# ATSAM4N16C register map
Vendor: Atmel; Series: SAM4N; File version: 0
CPU: CM4 r0p1, selectable endian, MPU, no FPU, 4 interrupt priority bits
Registers are 32-bit, read-write, reset 0x0 unless marked. A register's access mark holds for its fields unless they carry their own. Offsets are from the block's base; [hi:lo] are bit positions; {n}, {i} and the like mark numbered series; 'fields as' and 'values as' point back to an identical list.

## ADC — Analog-to-Digital Converter
Base 0x40038000; register names take the prefix ADC_
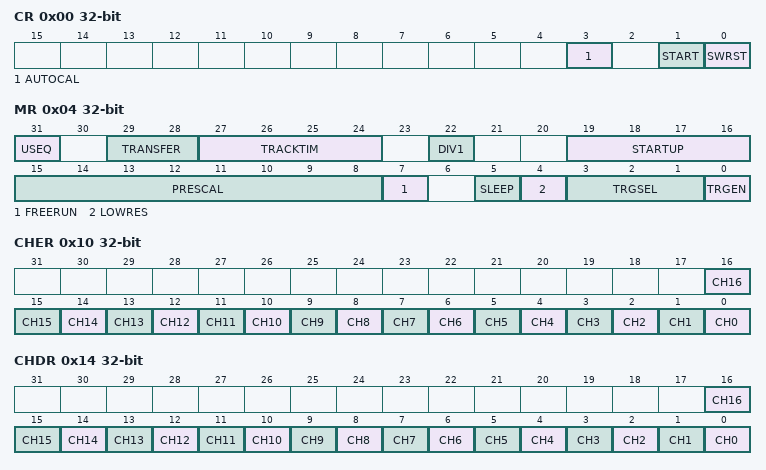
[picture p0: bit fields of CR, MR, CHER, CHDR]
0x00 CR wo reset not defined — Control Register
  [3] AUTOCAL — Automatic Calibration of ADC
  [1] START — Start Conversion
  [0] SWRST — Software Reset
0x04 MR — Mode Register
  [31] USEQ — Use Sequence Enable
    0=NUM_ORDER (Normal Mode: The controller converts channels in a simple numeric order depending only on the channel index.); 1=REG_ORDER (User Sequence Mode: The sequence respects what is defined in ADC_SEQR1 and ADC_SEQR2 registers and can be used to convert several times the same channel.)
  [29:28] TRANSFER — Transfer Period
  [27:24] TRACKTIM — Tracking Time
  [22] DIV1
  [19:16] STARTUP — Start Up Time
    0=SUT0 (0 periods of ADCClock); 1=SUT8 (8 periods of ADCClock); 2=SUT16 (16 periods of ADCClock); 3=SUT24 (24 periods of ADCClock); 4=SUT64 (64 periods of ADCClock); 5=SUT80 (80 periods of ADCClock); 6=SUT96 (96 periods of ADCClock); 7=SUT112 (112 periods of ADCClock); 8=SUT512 (512 periods of ADCClock); 9=SUT576 (576 periods of ADCClock); 10=SUT640 (640 periods of ADCClock); 11=SUT704 (704 periods of ADCClock); 12=SUT768 (768 periods of ADCClock); 13=SUT832 (832 periods of ADCClock); 14=SUT896 (896 periods of ADCClock); 15=SUT960 (960 periods of ADCClock)
  [15:8] PRESCAL — Prescaler Rate Selection
  [7] FREERUN — Free Run Mode
    0=OFF (Normal Mode); 1=ON (Free Run Mode: Never wait for any trigger.)
  [5] SLEEP — Sleep Mode
    0=NORMAL (Normal Mode: The ADC Core and reference voltage circuitry are kept ON between conversions); 1=SLEEP (Sleep Mode: The ADC Core and reference voltage circuitry are OFF between conversions)
  [4] LOWRES — Resolution
    0=BITS_10 (10-bit resolution. For higher resolution by interpolation, please refer to "ADC Extended Mode Register" on page 81); 1=BITS_8 (8-bit resolution)
  [3:1] TRGSEL — Trigger Selection
    0=ADC_TRIG0 (External trigger); 1=ADC_TRIG1 (TIO Output of the Timer Counter Channel 0); 2=ADC_TRIG2 (TIO Output of the Timer Counter Channel 1); 3=ADC_TRIG3 (TIO Output of the Timer Counter Channel 2)
  [0] TRGEN — Trigger Enable
    0=DIS (Hardware triggers are disabled. Starting a conversion is only possible by software.); 1=EN (Hardware trigger selected by TRGSEL field is enabled.)
{0x8+4i} SEQR[{i}] (i=0..1) reset not defined — Channel Sequence Register
0x10 CHER wo reset not defined — Channel Enable Register
  [n] CH{n} (n=0..16) — Channel {n} Enable
0x14 CHDR wo reset not defined — Channel Disable Register
  [n] CH{n} (n=0..16) — Channel {n} Disable
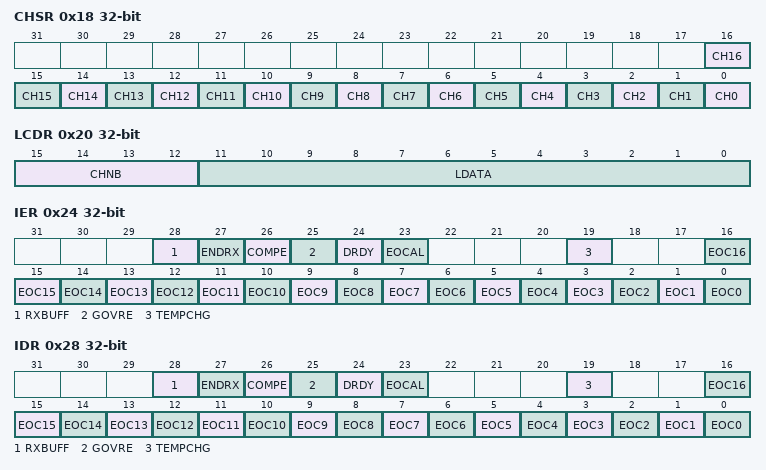
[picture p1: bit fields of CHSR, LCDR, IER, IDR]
0x18 CHSR ro — Channel Status Register
  [n] CH{n} (n=0..16) — Channel {n} Status
0x20 LCDR ro — Last Converted Data Register
  [15:12] CHNB — Channel Number
  [11:0] LDATA — Last Data Converted
0x24 IER wo reset not defined — Interrupt Enable Register
  [28] RXBUFF — Receive Buffer Full Interrupt Enable
  [27] ENDRX — End of Receive Buffer Interrupt Enable
  [26] COMPE — Comparison Event Interrupt Enable
  [25] GOVRE — General Overrun Error Interrupt Enable
  [24] DRDY — Data Ready Interrupt Enable
  [23] EOCAL — End of Calibration Sequence
  [19] TEMPCHG — Temperature Change Interrupt Enable
  [n] EOC{n} (n=0..16) — End of Conversion Interrupt Enable {n}
0x28 IDR wo reset not defined — Interrupt Disable Register
  [28] RXBUFF — Receive Buffer Full Interrupt Disable
  [27] ENDRX — End of Receive Buffer Interrupt Disable
  [26] COMPE — Comparison Event Interrupt Disable
  [25] GOVRE — General Overrun Error Interrupt Disable
  [24] DRDY — Data Ready Interrupt Disable
  [23] EOCAL — End of Calibration Sequence
  [19] TEMPCHG — Temperature Change Interrupt Disable
  [n] EOC{n} (n=0..16) — End of Conversion Interrupt Disable {n}
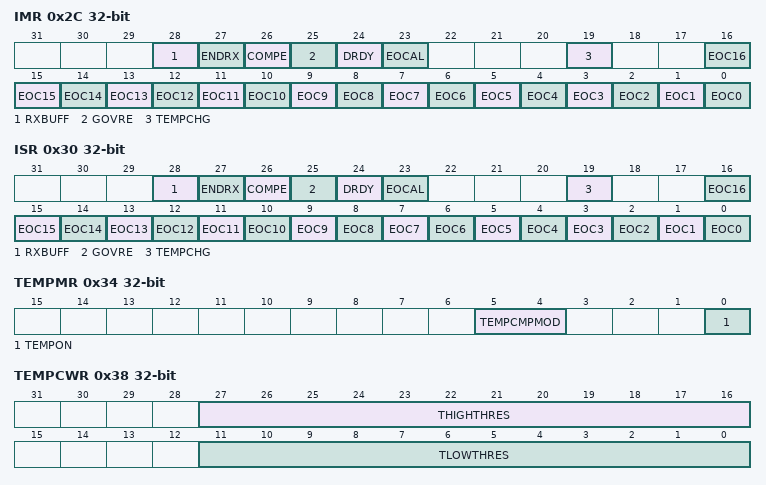
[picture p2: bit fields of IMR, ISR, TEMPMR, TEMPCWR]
0x2C IMR ro — Interrupt Mask Register
  [28] RXBUFF — Receive Buffer Full Interrupt Mask
  [27] ENDRX — End of Receive Buffer Interrupt Mask
  [26] COMPE — Comparison Event Interrupt Mask
  [25] GOVRE — General Overrun Error Interrupt Mask
  [24] DRDY — Data Ready Interrupt Mask
  [23] EOCAL — End of Calibration Sequence
  [19] TEMPCHG — Temperature Change Interrupt Mask
  [n] EOC{n} (n=0..16) — End of Conversion Interrupt Mask {n}
0x30 ISR ro — Interrupt Status Register
  [28] RXBUFF — RX Buffer Full
  [27] ENDRX — End of RX Buffer
  [26] COMPE — Comparison Error
  [25] GOVRE — General Overrun Error
  [24] DRDY — Data Ready
  [23] EOCAL — End of Calibration Sequence
  [19] TEMPCHG — Temperature Change
  [n] EOC{n} (n=0..16) — End of Conversion {n}
0x34 TEMPMR — Temperature Sensor Mode Register
  [5:4] TEMPCMPMOD — Temperature Comparison Mode
    0=LOW (Generates an event when the converted data is lower than the low threshold of the window.); 1=HIGH (Generates an event when the converted data is higher than the high threshold of the window.); 2=IN (Generates an event when the converted data is in the comparison window.); 3=OUT (Generates an event when the converted data is out of the comparison window.)
  [0] TEMPON — Temperature Sensor ON
0x38 TEMPCWR — Temperature Compare Window Register
  [27:16] THIGHTHRES — Temperature High Threshold
  [11:0] TLOWTHRES — Temperature Low Threshold
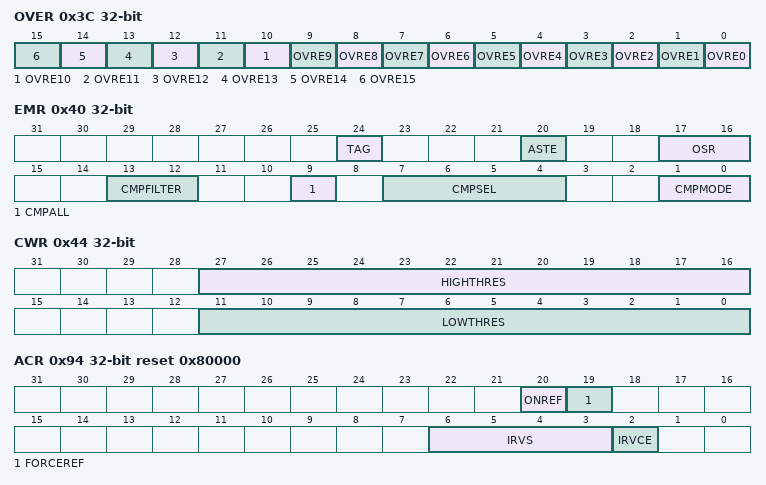
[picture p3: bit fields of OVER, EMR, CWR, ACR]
0x3C OVER ro — Overrun Status Register
  [n] OVRE{n} (n=0..15) — Overrun Error {n}
0x40 EMR — Extended Mode Register
  [24] TAG — TAG of the ADC_LDCR register
  [20] ASTE — Averaging on Single Trigger Event
    0=MULTI_TRIG_AVERAGE (The average requests several trigger events.); 1=SINGLE_TRIG_AVERAGE (The average requests only one trigger event.)
  [17:16] OSR — Over Sampling Rate
    0=NO_AVERAGE (no averaging. ADC sample rate is maximum.); 1=1-bit enhanced resolution by interpolation. ADC sample rate divided by 4.; 2=2-bit enhanced resolution by interpolation. ADC sample rate divided by 16.
  [13:12] CMPFILTER — Compare Event Filtering
  [9] CMPALL — Compare All Channels
  [7:4] CMPSEL — Comparison Selected Channel
  [1:0] CMPMODE — Comparison Mode
    values as TEMPMR.TEMPCMPMOD
0x44 CWR — Compare Window Register
  [27:16] HIGHTHRES — High Threshold
  [11:0] LOWTHRES — Low Threshold
{0x50+4i} CDR[{i}] (i=0..16) ro reset not defined — Channel Data Register
  [11:0] DATA — Converted Data
0x94 ACR reset 0x80000 — Analog Control Register
  [20] ONREF — Internal Voltage Reference ON
  [19] FORCEREF — Force Internal Reference Voltage
  [6:3] IRVS — Internal Reference Voltage Selection
  [2] IRVCE — Internal Reference Voltage Change Enable
    0=STUCK_AT_DEFAULT (The internal reference voltage is stuck at the default value (see the product electrical charac-teristics for further details).); 1=SELECTION (The internal reference voltage is defined by field IRVS.)
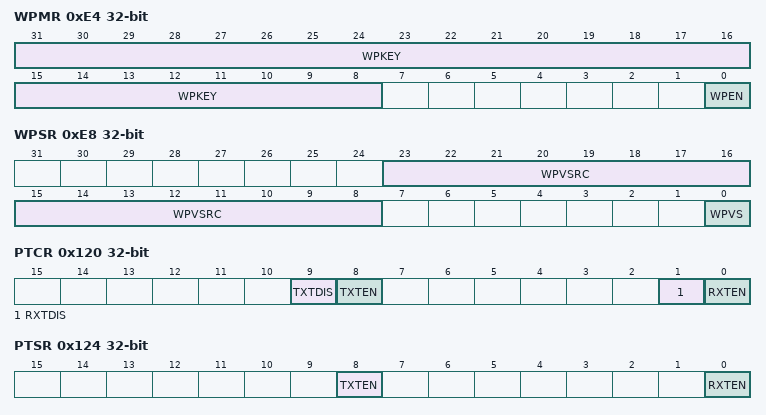
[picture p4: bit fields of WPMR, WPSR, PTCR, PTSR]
0xE4 WPMR — Write Protect Mode Register
  [31:8] WPKEY — Write Protect KEY
    0x414443=PASSWD (Writing any other value in this field aborts the write operation of the WPEN bit.Always reads as 0)
  [0] WPEN — Write Protect Enable
0xE8 WPSR ro — Write Protect Status Register
  [23:8] WPVSRC — Write Protect Violation Source
  [0] WPVS — Write Protect Violation Status
0x100 RPR — Receive Pointer Register
  [31:0] RXPTR
0x104 RCR — Receive Counter Register
  [15:0] RXCTR
0x110 RNPR — Receive Next Pointer Register
  [31:0] RXNPTR — Receive Next Pointer
0x114 RNCR — Receive Next Counter Register
  [15:0] RXNCTR — Receive Next Counter
0x120 PTCR wo — Transfer Control Register
  [9] TXTDIS — Transmitter Transfer Disable
  [8] TXTEN — Transmitter Transfer Enable
  [1] RXTDIS — Receiver Transfer Disable
  [0] RXTEN — Receiver Transfer Enable
0x124 PTSR ro — Transfer Status Register
  [8] TXTEN — Transmitter Transfer Enable
  [0] RXTEN — Receiver Transfer Enable

## Notices in the file
SAM Software Package License
Copyright (c) 2014, Atmel Corporation
All rights reserved.
Redistribution and use in source and binary forms, with or without
modification, are permitted provided that the following condition is met:
- Redistributions of source code must retain the above copyright notice,
this list of conditions and the disclaimer below.
Atmel's name may not be used to endorse or promote products derived from
this software without specific prior written permission.
DISCLAIMER:  THIS SOFTWARE IS PROVIDED BY ATMEL "AS IS" AND ANY EXPRESS OR
IMPLIED WARRANTIES, INCLUDING, BUT NOT LIMITED TO, THE IMPLIED WARRANTIES OF
MERCHANTABILITY, FITNESS FOR A PARTICULAR PURPOSE AND NON-INFRINGEMENT ARE
DISCLAIMED. IN NO EVENT SHALL ATMEL BE LIABLE FOR ANY DIRECT, INDIRECT,
INCIDENTAL, SPECIAL, EXEMPLARY, OR CONSEQUENTIAL DAMAGES (INCLUDING, BUT NOT
LIMITED TO, PROCUREMENT OF SUBSTITUTE GOODS OR SERVICES; LOSS OF USE, DATA,
OR PROFITS; OR BUSINESS INTERRUPTION) HOWEVER CAUSED AND ON ANY THEORY OF
LIABILITY, WHETHER IN CONTRACT, STRICT LIABILITY, OR TORT (INCLUDING
NEGLIGENCE OR OTHERWISE) ARISING IN ANY WAY OUT OF THE USE OF THIS SOFTWARE,
EVEN IF ADVISED OF THE POSSIBILITY OF SUCH DAMAGE.
